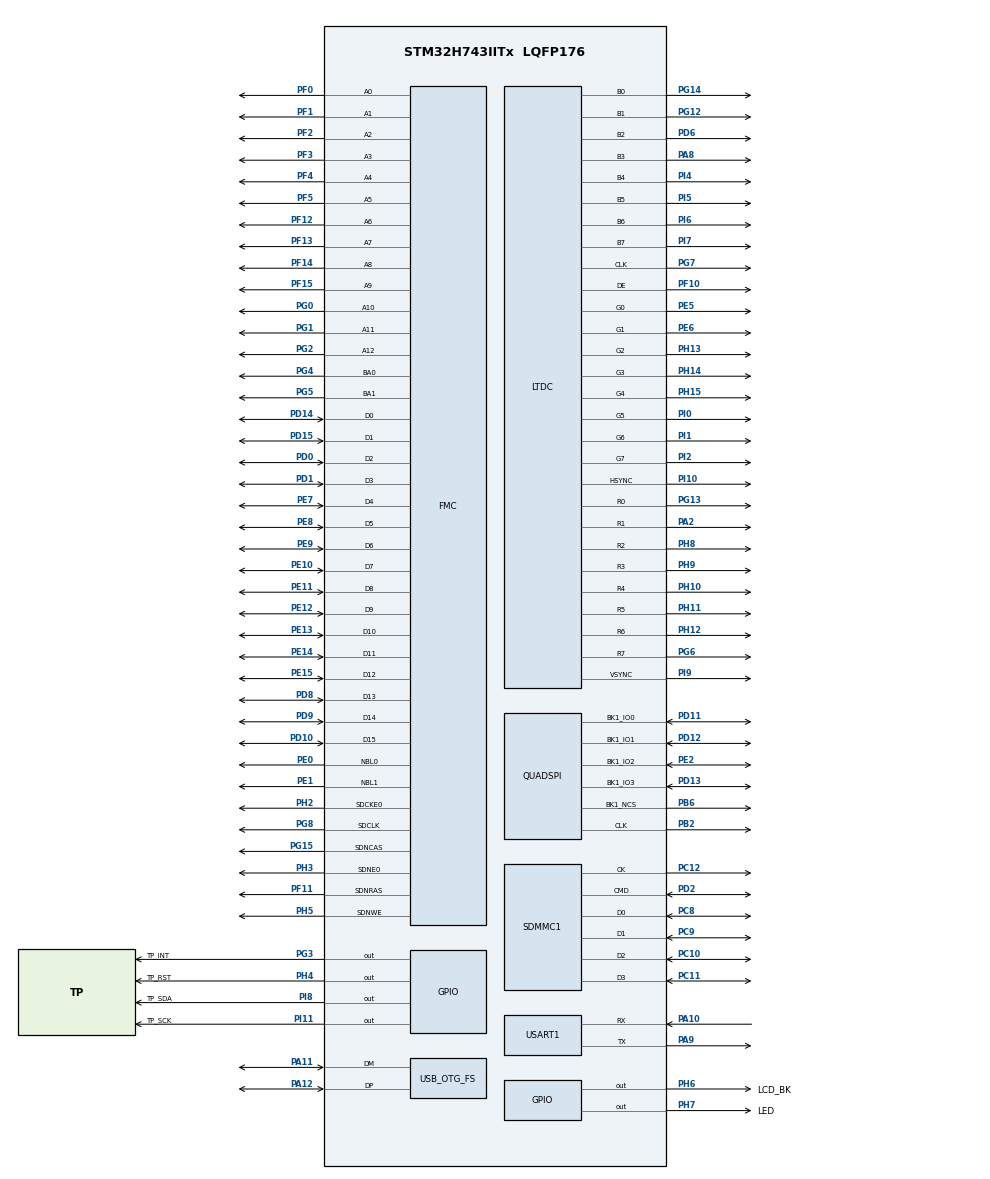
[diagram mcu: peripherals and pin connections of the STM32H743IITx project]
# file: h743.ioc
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CORTEX_M7.AccessPermission-Cortex_Memory_Protection_Unit_Region0_Settings=MPU_REGION_FULL_ACCESS
CORTEX_M7.AccessPermission-Cortex_Memory_Protection_Unit_Region1_Settings=MPU_REGION_FULL_ACCESS
CORTEX_M7.BaseAddress-Cortex_Memory_Protection_Unit_Region0_Settings=0xC0000000
CORTEX_M7.BaseAddress-Cortex_Memory_Protection_Unit_Region1_Settings=0x30000000
CORTEX_M7.CPU_DCache=Enabled
CORTEX_M7.CPU_ICache=Enabled
CORTEX_M7.DisableExec-Cortex_Memory_Protection_Unit_Region1_Settings=MPU_INSTRUCTION_ACCESS_DISABLE
CORTEX_M7.Enable-Cortex_Memory_Protection_Unit_Region0_Settings=MPU_REGION_ENABLE
CORTEX_M7.Enable-Cortex_Memory_Protection_Unit_Region1_Settings=MPU_REGION_ENABLE
CORTEX_M7.IsCacheable-Cortex_Memory_Protection_Unit_Region0_Settings=MPU_ACCESS_CACHEABLE
CORTEX_M7.IsShareable-Cortex_Memory_Protection_Unit_Region1_Settings=MPU_ACCESS_SHAREABLE
CORTEX_M7.MPU_Control=MPU_PRIVILEGED_DEFAULT
CORTEX_M7.Size-Cortex_Memory_Protection_Unit_Region0_Settings=MPU_REGION_SIZE_32MB
CORTEX_M7.Size-Cortex_Memory_Protection_Unit_Region1_Settings=MPU_REGION_SIZE_256KB
Dma.Request0=USART1_RX
Dma.Request1=USART1_TX
Dma.USART1_RX.0.Direction=DMA_PERIPH_TO_MEMORY
Dma.USART1_RX.0.EventEnable=DISABLE
Dma.USART1_RX.0.FIFOMode=DMA_FIFOMODE_DISABLE
Dma.USART1_RX.0.Instance=DMA1_Stream0
Dma.USART1_RX.0.MemDataAlignment=DMA_MDATAALIGN_BYTE
Dma.USART1_RX.0.MemInc=DMA_MINC_ENABLE
Dma.USART1_RX.0.Mode=DMA_NORMAL
Dma.USART1_RX.0.PeriphDataAlignment=DMA_PDATAALIGN_BYTE
Dma.USART1_RX.0.PeriphInc=DMA_PINC_DISABLE
Dma.USART1_RX.0.Polarity=HAL_DMAMUX_REQ_GEN_RISING
Dma.USART1_RX.0.Priority=DMA_PRIORITY_LOW
Dma.USART1_RX.0.RequestNumber=1
Dma.USART1_RX.0.SignalID=NONE
Dma.USART1_RX.0.SyncEnable=DISABLE
Dma.USART1_RX.0.SyncPolarity=HAL_DMAMUX_SYNC_NO_EVENT
Dma.USART1_RX.0.SyncRequestNumber=1
Dma.USART1_RX.0.SyncSignalID=NONE
Dma.USART1_TX.1.Direction=DMA_MEMORY_TO_PERIPH
Dma.USART1_TX.1.EventEnable=DISABLE
Dma.USART1_TX.1.FIFOMode=DMA_FIFOMODE_DISABLE
Dma.USART1_TX.1.Instance=DMA1_Stream1
Dma.USART1_TX.1.MemDataAlignment=DMA_MDATAALIGN_BYTE
Dma.USART1_TX.1.MemInc=DMA_MINC_ENABLE
Dma.USART1_TX.1.Mode=DMA_NORMAL
Dma.USART1_TX.1.PeriphDataAlignment=DMA_PDATAALIGN_BYTE
Dma.USART1_TX.1.PeriphInc=DMA_PINC_DISABLE
Dma.USART1_TX.1.Polarity=HAL_DMAMUX_REQ_GEN_RISING
Dma.USART1_TX.1.Priority=DMA_PRIORITY_LOW
Dma.USART1_TX.1.RequestNumber=1
Dma.USART1_TX.1.SignalID=NONE
Dma.USART1_TX.1.SyncEnable=DISABLE
Dma.USART1_TX.1.SyncPolarity=HAL_DMAMUX_SYNC_NO_EVENT
Dma.USART1_TX.1.SyncRequestNumber=1
Dma.USART1_TX.1.SyncSignalID=NONE
FMC.CASLatency1=FMC_SDRAM_CAS_LATENCY_3
FMC.ColumnBitsNumber1=FMC_SDRAM_COLUMN_BITS_NUM_9
FMC.ExitSelfRefreshDelay1=7
FMC.LoadToActiveDelay1=2
FMC.RPDelay1=2
FMC.RPDelay2=2
FMC.ReadBurst1=FMC_SDRAM_RBURST_ENABLE
FMC.ReadBurst2=FMC_SDRAM_RBURST_ENABLE
FMC.ReadPipeDelay1=FMC_SDRAM_RPIPE_DELAY_1
FMC.ReadPipeDelay2=FMC_SDRAM_RPIPE_DELAY_1
FMC.RowCycleDelay1=7
FMC.RowCycleDelay2=7
FMC.SDClockPeriod1=FMC_SDRAM_CLOCK_PERIOD_2
FMC.SDClockPeriod2=FMC_SDRAM_CLOCK_PERIOD_2
FMC.SelfRefreshTime1=4
FMC.WriteRecoveryTime1=2
LTDC.ActiveW=800
LTDC.Alpha_L0=255
LTDC.FBStartAdress_L0=0
LTDC.HBP=46
LTDC.HFP=200
LTDC.HSync=1
LTDC.ImageHeight_L0=480
LTDC.ImageWidth_L0=800
LTDC.Layers=0
LTDC.PixelFormat_L0=LTDC_PIXEL_FORMAT_RGB565
LTDC.VBP=23
LTDC.VFP=22
LTDC.VSync=1
LTDC.WindowX1_L0=800
LTDC.WindowY1_L0=480
Mcu.Family=STM32H7
Mcu.Name=STM32H743IITx
Mcu.Package=LQFP176
Mdma.MDMA_Channel0.QUADSPI_FIFO_TH.0.BlockCount=0
Mdma.MDMA_Channel0.QUADSPI_FIFO_TH.0.BlockDataLength=0
Mdma.MDMA_Channel0.QUADSPI_FIFO_TH.0.BufferTransferLength=128
Mdma.MDMA_Channel0.QUADSPI_FIFO_TH.0.CircularMode=MDMA_LINEAR_LIST
Mdma.MDMA_Channel0.QUADSPI_FIFO_TH.0.DataAlignment=MDMA_DATAALIGN_PACKENABLE
Mdma.MDMA_Channel0.QUADSPI_FIFO_TH.0.DestBlockAddressOffset=0
Mdma.MDMA_Channel0.QUADSPI_FIFO_TH.0.DestBurst=MDMA_DEST_BURST_SINGLE
Mdma.MDMA_Channel0.QUADSPI_FIFO_TH.0.DestDataSize=MDMA_DEST_DATASIZE_BYTE
Mdma.MDMA_Channel0.QUADSPI_FIFO_TH.0.DestinationInc=MDMA_DEST_INC_BYTE
Mdma.MDMA_Channel0.QUADSPI_FIFO_TH.0.DstAddress=0
Mdma.MDMA_Channel0.QUADSPI_FIFO_TH.0.Endianness=MDMA_LITTLE_ENDIANNESS_PRESERVE
Mdma.MDMA_Channel0.QUADSPI_FIFO_TH.0.Instance=MDMA_Channel0
Mdma.MDMA_Channel0.QUADSPI_FIFO_TH.0.MaskAddress=0
Mdma.MDMA_Channel0.QUADSPI_FIFO_TH.0.MaskData=0
Mdma.MDMA_Channel0.QUADSPI_FIFO_TH.0.Priority=MDMA_PRIORITY_VERY_HIGH
Mdma.MDMA_Channel0.QUADSPI_FIFO_TH.0.Rank=First
Mdma.MDMA_Channel0.QUADSPI_FIFO_TH.0.SourceBlockAddressOffset=0
Mdma.MDMA_Channel0.QUADSPI_FIFO_TH.0.SourceBurst=MDMA_SOURCE_BURST_SINGLE
Mdma.MDMA_Channel0.QUADSPI_FIFO_TH.0.SourceDataSize=MDMA_SRC_DATASIZE_BYTE
Mdma.MDMA_Channel0.QUADSPI_FIFO_TH.0.SourceInc=MDMA_SRC_INC_BYTE
Mdma.MDMA_Channel0.QUADSPI_FIFO_TH.0.SrcAddress=0
Mdma.MDMA_Channel0.QUADSPI_FIFO_TH.0.TransferTriggerMode=MDMA_BUFFER_TRANSFER
Mdma.MDMA_Channel0.Request0=QUADSPI_FIFO_TH
Mdma.MDMA_Channel0.RequestsNb=1
Mdma.RequestSet0=MDMA_Channel0
Mdma.RequestSetsNb=1
NVIC.DMA1_Stream0_IRQn=true\:5\:0\:true\:false\:true\:false\:true\:true
NVIC.DMA1_Stream1_IRQn=true\:5\:0\:true\:false\:true\:false\:true\:true
NVIC.LTDC_IRQn=true\:5\:0\:true\:false\:true\:true\:true\:true
NVIC.MDMA_IRQn=true\:5\:0\:true\:false\:true\:false\:true\:true
NVIC.PriorityGroup=NVIC_PRIORITYGROUP_4
NVIC.QUADSPI_IRQn=true\:5\:0\:true\:false\:true\:true\:true\:true
NVIC.SDMMC1_IRQn=true\:5\:0\:true\:false\:true\:true\:true\:true
NVIC.TIM7_IRQn=true\:15\:0\:false\:false\:true\:false\:true\:true
NVIC.TimeBase=TIM7_IRQn
NVIC.TimeBaseIP=TIM7
NVIC.USART1_IRQn=true\:5\:0\:true\:false\:true\:true\:true\:true
PA10.Mode=Asynchronous
PA10.Signal=USART1_RX
PA11.Mode=Device_Only
PA11.Signal=USB_OTG_FS_DM
PA12.Mode=Device_Only
PA12.Signal=USB_OTG_FS_DP
PA13\ (JTMS/SWDIO).Mode=Serial_Wire
PA13\ (JTMS/SWDIO).Signal=DEBUG_JTMS-SWDIO
PA14\ (JTCK/SWCLK).Mode=Serial_Wire
PA14\ (JTCK/SWCLK).Signal=DEBUG_JTCK-SWCLK
PA2.GPIO_Speed=GPIO_SPEED_FREQ_VERY_HIGH
PA2.Mode=RGB888
PA2.Signal=LTDC_R1
PA8.GPIO_Speed=GPIO_SPEED_FREQ_VERY_HIGH
PA8.Mode=RGB888
PA8.Signal=LTDC_B3
PA9.Mode=Asynchronous
PA9.Signal=USART1_TX
PB2.GPIO_Speed=GPIO_SPEED_FREQ_VERY_HIGH
PB2.Mode=Single Bank 1
PB2.Signal=QUADSPI_CLK
PB6.GPIO_Speed=GPIO_SPEED_FREQ_VERY_HIGH
PB6.Mode=Single Bank 1
PB6.Signal=QUADSPI_BK1_NCS
PC10.Mode=SD_4_bits_Wide_bus
PC10.Signal=SDMMC1_D2
PC11.Mode=SD_4_bits_Wide_bus
PC11.Signal=SDMMC1_D3
PC12.Mode=SD_4_bits_Wide_bus
PC12.Signal=SDMMC1_CK
PC14-OSC32_IN\ (OSC32_IN).Mode=LSE-External-Oscillator
PC14-OSC32_IN\ (OSC32_IN).Signal=RCC_OSC32_IN
PC15-OSC32_OUT\ (OSC32_OUT).Mode=LSE-External-Oscillator
PC15-OSC32_OUT\ (OSC32_OUT).Signal=RCC_OSC32_OUT
PC8.Mode=SD_4_bits_Wide_bus
PC8.Signal=SDMMC1_D0
PC9.Mode=SD_4_bits_Wide_bus
PC9.Signal=SDMMC1_D1
PD0.Signal=FMC_D2_DA2
PD1.Signal=FMC_D3_DA3
PD10.Signal=FMC_D15_DA15
PD11.GPIO_Speed=GPIO_SPEED_FREQ_VERY_HIGH
PD11.Mode=Single Bank 1
PD11.Signal=QUADSPI_BK1_IO0
PD12.GPIO_Speed=GPIO_SPEED_FREQ_VERY_HIGH
PD12.Mode=Single Bank 1
PD12.Signal=QUADSPI_BK1_IO1
PD13.GPIO_Speed=GPIO_SPEED_FREQ_VERY_HIGH
PD13.Mode=Single Bank 1
PD13.Signal=QUADSPI_BK1_IO3
PD14.Signal=FMC_D0_DA0
PD15.Signal=FMC_D1_DA1
PD2.Mode=SD_4_bits_Wide_bus
PD2.Signal=SDMMC1_CMD
PD6.GPIO_Speed=GPIO_SPEED_FREQ_VERY_HIGH
PD6.Mode=RGB888
PD6.Signal=LTDC_B2
PD8.Signal=FMC_D13_DA13
PD9.Signal=FMC_D14_DA14
PE0.Signal=FMC_NBL0
PE1.Signal=FMC_NBL1
PE10.Signal=FMC_D7_DA7
PE11.Signal=FMC_D8_DA8
PE12.Signal=FMC_D9_DA9
PE13.Signal=FMC_D10_DA10
PE14.Signal=FMC_D11_DA11
PE15.Signal=FMC_D12_DA12
PE2.GPIO_Speed=GPIO_SPEED_FREQ_VERY_HIGH
PE2.Mode=Single Bank 1
PE2.Signal=QUADSPI_BK1_IO2
PE5.GPIO_Speed=GPIO_SPEED_FREQ_VERY_HIGH
PE5.Mode=RGB888
PE5.Signal=LTDC_G0
PE6.GPIO_Speed=GPIO_SPEED_FREQ_VERY_HIGH
PE6.Mode=RGB888
PE6.Signal=LTDC_G1
PE7.Signal=FMC_D4_DA4
PE8.Signal=FMC_D5_DA5
PE9.Signal=FMC_D6_DA6
PF0.Signal=FMC_A0
PF1.Signal=FMC_A1
PF10.GPIO_Speed=GPIO_SPEED_FREQ_VERY_HIGH
PF10.Mode=RGB888
PF10.Signal=LTDC_DE
PF11.Signal=FMC_SDNRAS
PF12.Signal=FMC_A6
PF13.Signal=FMC_A7
PF14.Signal=FMC_A8
PF15.Signal=FMC_A9
PF2.Signal=FMC_A2
PF3.Signal=FMC_A3
PF4.Signal=FMC_A4
PF5.Signal=FMC_A5
PG0.Signal=FMC_A10
PG1.Signal=FMC_A11
PG12.GPIO_Speed=GPIO_SPEED_FREQ_VERY_HIGH
PG12.Mode=RGB888
PG12.Signal=LTDC_B1
PG13.GPIO_Speed=GPIO_SPEED_FREQ_VERY_HIGH
PG13.Mode=RGB888
PG13.Signal=LTDC_R0
PG14.GPIO_Speed=GPIO_SPEED_FREQ_VERY_HIGH
PG14.Mode=RGB888
PG14.Signal=LTDC_B0
PG15.Signal=FMC_SDNCAS
PG2.Signal=FMC_A12
PG3.GPIO_Label=TP_INT
PG3.Signal=GPIO_Output
PG4.Signal=FMC_A14_BA0
PG5.Signal=FMC_A15_BA1
PG6.GPIO_Speed=GPIO_SPEED_FREQ_VERY_HIGH
PG6.Mode=RGB888
PG6.Signal=LTDC_R7
PG7.GPIO_Speed=GPIO_SPEED_FREQ_VERY_HIGH
PG7.Mode=RGB888
PG7.Signal=LTDC_CLK
PG8.Signal=FMC_SDCLK
PH0-OSC_IN\ (PH0).Mode=HSE-External-Oscillator
PH0-OSC_IN\ (PH0).Signal=RCC_OSC_IN
PH1-OSC_OUT\ (PH1).Mode=HSE-External-Oscillator
PH1-OSC_OUT\ (PH1).Signal=RCC_OSC_OUT
PH10.GPIO_Speed=GPIO_SPEED_FREQ_VERY_HIGH
PH10.Mode=RGB888
PH10.Signal=LTDC_R4
PH11.GPIO_Speed=GPIO_SPEED_FREQ_VERY_HIGH
PH11.Mode=RGB888
PH11.Signal=LTDC_R5
PH12.GPIO_Speed=GPIO_SPEED_FREQ_VERY_HIGH
PH12.Mode=RGB888
PH12.Signal=LTDC_R6
PH13.GPIO_Speed=GPIO_SPEED_FREQ_VERY_HIGH
PH13.Mode=RGB888
PH13.Signal=LTDC_G2
PH14.GPIO_Speed=GPIO_SPEED_FREQ_VERY_HIGH
PH14.Mode=RGB888
PH14.Signal=LTDC_G3
PH15.GPIO_Speed=GPIO_SPEED_FREQ_VERY_HIGH
PH15.Mode=RGB888
PH15.Signal=LTDC_G4
PH2.Mode=SdramChipSelect1_1
PH2.Signal=FMC_SDCKE0
PH3.Mode=SdramChipSelect1_1
PH3.Signal=FMC_SDNE0
PH4.GPIO_Label=TP_RST
PH4.Signal=GPIO_Output
PH5.Signal=FMC_SDNWE
PH6.GPIO_Label=LCD_BK
PH6.Signal=GPIO_Output
PH7.GPIO_Label=LED
PH7.Signal=GPIO_Output
PH8.GPIO_Speed=GPIO_SPEED_FREQ_VERY_HIGH
PH8.Mode=RGB888
PH8.Signal=LTDC_R2
PH9.GPIO_Speed=GPIO_SPEED_FREQ_VERY_HIGH
PH9.Mode=RGB888
PH9.Signal=LTDC_R3
PI0.GPIO_Speed=GPIO_SPEED_FREQ_VERY_HIGH
PI0.Mode=RGB888
PI0.Signal=LTDC_G5
PI1.GPIO_Speed=GPIO_SPEED_FREQ_VERY_HIGH
PI1.Mode=RGB888
PI1.Signal=LTDC_G6
PI10.GPIO_Speed=GPIO_SPEED_FREQ_VERY_HIGH
PI10.Mode=RGB888
PI10.Signal=LTDC_HSYNC
PI11.GPIO_Label=TP_SCK
PI11.Signal=GPIO_Output
PI2.GPIO_Speed=GPIO_SPEED_FREQ_VERY_HIGH
PI2.Mode=RGB888
PI2.Signal=LTDC_G7
PI4.GPIO_Speed=GPIO_SPEED_FREQ_VERY_HIGH
PI4.Mode=RGB888
PI4.Signal=LTDC_B4
PI5.GPIO_Speed=GPIO_SPEED_FREQ_VERY_HIGH
PI5.Mode=RGB888
PI5.Signal=LTDC_B5
PI6.GPIO_Speed=GPIO_SPEED_FREQ_VERY_HIGH
PI6.Mode=RGB888
PI6.Signal=LTDC_B6
PI7.GPIO_Speed=GPIO_SPEED_FREQ_VERY_HIGH
PI7.Mode=RGB888
PI7.Signal=LTDC_B7
PI8.GPIO_Label=TP_SDA
PI8.Signal=GPIO_Output
PI9.GPIO_Speed=GPIO_SPEED_FREQ_VERY_HIGH
PI9.Mode=RGB888
PI9.Signal=LTDC_VSYNC
ProjectManager.HeapSize=0x200
ProjectManager.StackSize=0x400
ProjectManager.TargetToolchain=STM32CubeIDE
QUADSPI.ChipSelectHighTime=QSPI_CS_HIGH_TIME_1_CYCLE
QUADSPI.ClockMode=QSPI_CLOCK_MODE_3
QUADSPI.ClockPrescaler=3-1
QUADSPI.FifoThreshold=32
QUADSPI.FlashSize=22
QUADSPI.SampleShifting=QSPI_SAMPLE_SHIFTING_HALFCYCLE
RCC.ADCFreq_Value=100000000
RCC.APB1Freq_Value=120000000
RCC.APB2Freq_Value=120000000
RCC.APB3Freq_Value=120000000
RCC.APB4Freq_Value=120000000
RCC.CortexFreq_Value=480000000
RCC.D1PPRE=RCC_APB3_DIV2
RCC.D2PPRE1=RCC_APB1_DIV2
RCC.D2PPRE2=RCC_APB2_DIV2
RCC.D3PPRE=RCC_APB4_DIV2
RCC.DIVM1=5
RCC.DIVM2=2
RCC.DIVM3=25
RCC.DIVN1=192
RCC.DIVN2=16
RCC.DIVN3=330
RCC.DIVQ1=20
RCC.DIVR1=4
RCC.DIVR2=1
RCC.DIVR3=10
RCC.FMCCLockSelection=RCC_FMCCLKSOURCE_PLL2
RCC.HCLKFreq_Value=240000000
RCC.HPRE=RCC_HCLK_DIV2
RCC.PLL2FRACN=0
RCC.PLL3FRACN=0
RCC.PLLFRACN=0
RCC.PLLSourceVirtual=RCC_PLLSOURCE_HSE
RCC.RTCClockSelection=RCC_RTCCLKSOURCE_LSE
RCC.SYSCLKFreq_VALUE=480000000
RCC.SYSCLKSource=RCC_SYSCLKSOURCE_PLLCLK
RCC.USBCLockSelection=RCC_USBCLKSOURCE_HSI48
RCC.USBFreq_Value=48000000
SDMMC1.ClockDiv=2
SH.FMC_A0.0=FMC_A0,13b-sda1
SH.FMC_A1.0=FMC_A1,13b-sda1
SH.FMC_A10.0=FMC_A10,13b-sda1
SH.FMC_A11.0=FMC_A11,13b-sda1
SH.FMC_A12.0=FMC_A12,13b-sda1
SH.FMC_A14_BA0.0=FMC_BA0,FourSdramBanks1
SH.FMC_A15_BA1.0=FMC_BA1,FourSdramBanks1
SH.FMC_A2.0=FMC_A2,13b-sda1
SH.FMC_A3.0=FMC_A3,13b-sda1
SH.FMC_A4.0=FMC_A4,13b-sda1
SH.FMC_A5.0=FMC_A5,13b-sda1
SH.FMC_A6.0=FMC_A6,13b-sda1
SH.FMC_A7.0=FMC_A7,13b-sda1
SH.FMC_A8.0=FMC_A8,13b-sda1
SH.FMC_A9.0=FMC_A9,13b-sda1
SH.FMC_D0_DA0.0=FMC_D0,sd-16b-d1
SH.FMC_D10_DA10.0=FMC_D10,sd-16b-d1
SH.FMC_D11_DA11.0=FMC_D11,sd-16b-d1
SH.FMC_D12_DA12.0=FMC_D12,sd-16b-d1
SH.FMC_D13_DA13.0=FMC_D13,sd-16b-d1
SH.FMC_D14_DA14.0=FMC_D14,sd-16b-d1
SH.FMC_D15_DA15.0=FMC_D15,sd-16b-d1
SH.FMC_D1_DA1.0=FMC_D1,sd-16b-d1
SH.FMC_D2_DA2.0=FMC_D2,sd-16b-d1
SH.FMC_D3_DA3.0=FMC_D3,sd-16b-d1
SH.FMC_D4_DA4.0=FMC_D4,sd-16b-d1
SH.FMC_D5_DA5.0=FMC_D5,sd-16b-d1
SH.FMC_D6_DA6.0=FMC_D6,sd-16b-d1
SH.FMC_D7_DA7.0=FMC_D7,sd-16b-d1
SH.FMC_D8_DA8.0=FMC_D8,sd-16b-d1
SH.FMC_D9_DA9.0=FMC_D9,sd-16b-d1
SH.FMC_NBL0.0=FMC_NBL0,Sd2ByteEnable1
SH.FMC_NBL1.0=FMC_NBL1,Sd2ByteEnable1
SH.FMC_SDCLK.0=FMC_SDCLK,13b-sda1
SH.FMC_SDNCAS.0=FMC_SDNCAS,13b-sda1
SH.FMC_SDNRAS.0=FMC_SDNRAS,13b-sda1
SH.FMC_SDNWE.0=FMC_SDNWE,13b-sda1
USART1.VirtualMode-Asynchronous=VM_ASYNC
USB_OTG_FS.VirtualMode=Device_Only
VP_DMA2D_VS_DMA2D.Mode=DMA2D_Activate
VP_MEMORYMAP_VS_MEMORYMAP.Mode=CurAppReg
VP_RTC_VS_RTC_Activate.Mode=RTC_Enabled
VP_RTC_VS_RTC_Calendar.Mode=RTC_Calendar
VP_SYS_VS_tim7.Mode=TIM7
board=custom

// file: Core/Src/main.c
/* USER CODE BEGIN Header */
/**
  ******************************************************************************
  * @file           : main.c
  * @brief          : Main program body
  ******************************************************************************
  * @attention
  *
  * Copyright (c) 2026 STMicroelectronics.
  * All rights reserved.
  *
  * This software is licensed under terms that can be found in the LICENSE file
  * in the root directory of this software component.
  * If no LICENSE file comes with this software, it is provided AS-IS.
  *
  ******************************************************************************
  */
/* USER CODE END Header */
#include "main.h"
#include "dma.h"
#include "dma2d.h"
#include "ltdc.h"
#include "mdma.h"
#include "quadspi.h"
#include "rtc.h"
#include "sdmmc.h"
#include "usart.h"
#include "usb_otg.h"
#include "gpio.h"
#include "fmc.h"

/* USER CODE BEGIN Includes */
#include <string.h>
#include <stdio.h>
#include <stdarg.h>
#include <fcntl.h>
#include <unistd.h>
#include <time.h>

#include "fatfs_port.h"
#include "bsp/board_api.h"
#include "qspi_w25q64.h"
#include "tusb_port.h"
#include "sdram.h"
#include "mem.h"
#include "freertos_port.h"
#include "sd.h"
#include "tlsf_port.h"
#include "lcd.h"
#include "uart.h"
#include "usb_msc.h"
#include "usb_vdb.h"
#include "lcd.h"
#include "lv_port.h"
#include "lvgl.h"
#include "touch.h"
/* USER CODE END Includes */

void SystemClock_Config(void);
static void MPU_Config(void);

/* USER CODE BEGIN 0 */

// Zeller 公式计算星期几 (RTC编码: 1=Mon..7=Sun)
static int calc_weekday(int year, int month, int day)
{
    // Zeller's congruence (Gregorian calendar)
    if (month < 3) { month += 12; year--; }
    int k = year % 100;
    int j = year / 100;
    int h = (day + (13 * (month + 1)) / 5 + k + k / 4 + j / 4 - 2 * j) % 7;
    if (h < 0) h += 7;
    // h: 0=Sat, 1=Sun, 2=Mon ... 6=Fri
    // RTC: 1=Mon, 2=Tue, 3=Wed, 4=Thu, 5=Fri, 6=Sat, 7=Sun
    static const int map[] = {6, 7, 1, 2, 3, 4, 5};
    return map[h];
}

// 解析 __DATE__/__TIME__ 编译时间写入RTC (编译时刻=启动时间)
static void set_rtc_from_build_time(void)
{
    static const char *months[] = {
        "Jan", "Feb", "Mar", "Apr", "May", "Jun",
        "Jul", "Aug", "Sep", "Oct", "Nov", "Dec"
    };

    RTC_TimeTypeDef sTime = {0};
    RTC_DateTypeDef sDate = {0};

    int hour, minute, second;
    sscanf(__TIME__, "%d:%d:%d", &hour, &minute, &second);
    sTime.Hours   = hour;
    sTime.Minutes = minute;
    sTime.Seconds = second;
    sTime.DayLightSaving = RTC_DAYLIGHTSAVING_NONE;
    sTime.StoreOperation = RTC_STOREOPERATION_RESET;

    char mon_str[4];
    int day, year;
    sscanf(__DATE__, "%3s %d %d", mon_str, &day, &year);

    int month = 1;
    for (int i = 0; i < 12; i++) {
        if (strncmp(mon_str, months[i], 3) == 0) {
            month = i + 1;
            break;
        }
    }

    sDate.WeekDay = calc_weekday(year, month, day);
    sDate.Month   = month;
    sDate.Date    = day;
    sDate.Year    = year - 2000;

    HAL_RTC_SetTime(&hrtc, &sTime, RTC_FORMAT_BIN);
    HAL_RTC_SetDate(&hrtc, &sDate, RTC_FORMAT_BIN);
}

#if BSP_FREERTOS_ENABLED
static StackType_t  led_task_stack[128];
static StaticTask_t led_task_tcb;
// LED 闪烁任务 (100ms 周期, FreeRTOS)
static void led_task(void *pvParameters)
{
    (void)pvParameters;
    for (;;) {
        HAL_GPIO_TogglePin(LED_GPIO_Port, LED_Pin);
        vTaskDelay(pdMS_TO_TICKS(100));
    }
}

static StackType_t  usb_task_stack[512];
static StaticTask_t usb_task_tcb;
// USB 设备轮询任务 (1ms 周期, FreeRTOS)
static void usb_task(void *pvParameters)
{
    (void)pvParameters;
    for (;;) {
        tusb_port_task();
        usb_vdb_poll();
        vTaskDelay(pdMS_TO_TICKS(1));
    }
}

static StackType_t  lvgl_task_stack[4096];
static StaticTask_t lvgl_task_tcb;
// LVGL 任务: 初始化显示 + timer 心跳 (FreeRTOS)
static void lvgl_task(void *pvParameters)
{
  (void)pvParameters;
  lv_port_init();

  // 简单按钮示例
  lv_obj_t *btn = lv_slider_create(lv_screen_active());
  lv_obj_set_size(btn, 600, 50);
  lv_obj_center(btn);

  for (;;) {
    lv_timer_handler();
    vTaskDelay(pdMS_TO_TICKS(5));
  };
}

static StackType_t  touch_task_stack[256];
static StaticTask_t touch_task_tcb;
// 触摸扫描任务 (10ms 周期, FreeRTOS)
static void touch_task(void *pvParameters)
{
    (void)pvParameters;
    for (;;) {
        touch_scan();
        if (touch_is_touch()) {
            uint16_t x, y;
            touch_read_xy(0, &x, &y);
        }
        vTaskDelay(pdMS_TO_TICKS(10));
    }
}

static StackType_t  init_task_stack[1024];
static StaticTask_t init_task_tcb;
static char buff[64];
// 初始化任务: RTOS资源/LCD测试/UART回传+时间戳 (FreeRTOS)
static void init_task(void *pvParameters)
{
    (void)pvParameters;
    tlsf_port_rtos_init();
    sd_rtos_init();
    uart_rtos_init();
    touch_rtos_init();

    xTaskCreateStatic(led_task, "led", 128, NULL, 1,
                       led_task_stack, &led_task_tcb);
    xTaskCreateStatic(usb_task, "usb", 512, NULL, 2,
                       usb_task_stack, &usb_task_tcb);
    xTaskCreateStatic(lvgl_task, "lvgl", 4096, NULL, 4,
                       lvgl_task_stack, &lvgl_task_tcb);
    xTaskCreateStatic(touch_task, "touch", 256, NULL, 1,
                       touch_task_stack, &touch_task_tcb);

    int uart = open("/dev/uart/COM0", O_RDWR);
    if (uart == -1) {
      printf("open failed\n");
      return;
    }

    while (1) {
      int s = read(uart, buff, sizeof(buff));
      if (s > 0) {
        time_t now = time(NULL);
        struct tm *tm_info = localtime(&now);
        char time_str[64];
        int n = strftime(time_str, sizeof(time_str),
                         "[%Y-%m-%d %H:%M:%S] ", tm_info);
        if (n > 0) {
          write(uart, time_str, n);
        }
        write(uart, buff, s);
      }
      vTaskDelay(pdMS_TO_TICKS(10));
    };
}

#endif
/* USER CODE END 0 */

int main(void)
{

  /* MPU Configuration--------------------------------------------------------*/
  MPU_Config();

  /* Enable the CPU Cache */

  /* Enable I-Cache---------------------------------------------------------*/
  SCB_EnableICache();

  /* Enable D-Cache---------------------------------------------------------*/
  SCB_EnableDCache();

  /* MCU Configuration--------------------------------------------------------*/

  /* Reset of all peripherals, Initializes the Flash interface and the Systick. */
  HAL_Init();

  /* Configure the system clock */
  SystemClock_Config();

  /* Initialize all configured peripherals */
  MX_GPIO_Init();
  MX_MDMA_Init();
  MX_DMA_Init();
  MX_QUADSPI_Init();
  MX_USB_OTG_FS_PCD_Init();
  MX_USART1_UART_Init();
  MX_FMC_Init();
  MX_SDMMC1_SD_Init();
  MX_RTC_Init();
  MX_LTDC_Init();
  MX_DMA2D_Init();
  /* USER CODE BEGIN 2 */
  set_rtc_from_build_time();
  qspi_w25q64_init();              // 初始化W25Q64
  qspi_w25q64_memory_mapped_mode(); // 启用内存映射，之后才能读 EX_FLASH
  FMC_SDRAM_CommandTypeDef command;	// 控制指令
  sdram_init_sequence(&hsdram1,&command);
  mem_itcm_load();       // 搬运 ITCM 函数
  mem_sdram_load();      // 搬运 SDRAM 函数 (从 EX_FLASH 读取)
  tlsf_port_init();
  sd_init();              // 初始化 SD 卡
  fatfs_port_init();      // 挂载 SD 卡文件系统 (f_mount)
  fatfs_port_vfs_init();  // 注册 VFS 节点 (根 "/sd")
  usb_msc_init();         // 缓存 SD 卡信息 (必须在 tusb_port_init 之前)
  usb_vdb_init();          // 初始化 USB VDB
  tusb_port_init();       // 初始化 TinyUSB 设备
  uart_init();                     // UART RXNE 中断在硬件初始化完成后才开启
  uart_vfs_init();
  lcd_init();
  touch_init();

#if BSP_FREERTOS_ENABLED
  xTaskCreateStatic(init_task, "init", 1024, NULL, 3,
                     init_task_stack, &init_task_tcb);
  freertos_port_init();
#endif
  /* USER CODE END 2 */

  /* Infinite loop */
  /* USER CODE BEGIN WHILE */
#if !BSP_FREERTOS_ENABLED
  lv_port_init();
  lv_tick_set_cb(lv_port_tick_get);

  lv_obj_t *btn = lv_button_create(lv_screen_active());
  lv_obj_set_size(btn, 120, 50);
  lv_obj_center(btn);
  lv_obj_t *label = lv_label_create(btn);
  lv_label_set_text(label, "Hello");
  lv_obj_center(label);

  uint32_t t = HAL_GetTick();
  touch_init();
  while (1)
  {
    lv_timer_handler();
    touch_scan();
    if (touch_is_touch()) {
      uint16_t x, y;
      touch_read_xy(0, &x, &y);
      DEBUG_PRINT("Touch: %d pts, x0=%d y0=%d\r\n",
                  touch_get_num(), x, y);
    }
    if (HAL_GetTick()-t > 100) {
      HAL_GPIO_TogglePin(LED_GPIO_Port, LED_Pin);
      t = HAL_GetTick();
    }
    /* USER CODE END WHILE */

    /* USER CODE BEGIN 3 */
  }
#endif
  /* USER CODE END 3 */
}

void SystemClock_Config(void)
{
  RCC_OscInitTypeDef RCC_OscInitStruct = {0};
  RCC_ClkInitTypeDef RCC_ClkInitStruct = {0};

  /** Supply configuration update enable
  */
  HAL_PWREx_ConfigSupply(PWR_LDO_SUPPLY);

  /** Configure the main internal regulator output voltage
  */
  __HAL_PWR_VOLTAGESCALING_CONFIG(PWR_REGULATOR_VOLTAGE_SCALE0);

  while(!__HAL_PWR_GET_FLAG(PWR_FLAG_VOSRDY)) {}

  /** Configure LSE Drive Capability
  */
  HAL_PWR_EnableBkUpAccess();
  __HAL_RCC_LSEDRIVE_CONFIG(RCC_LSEDRIVE_LOW);

  /** Initializes the RCC Oscillators according to the specified parameters
  * in the RCC_OscInitTypeDef structure.
  */
  RCC_OscInitStruct.OscillatorType = RCC_OSCILLATORTYPE_HSI48|RCC_OSCILLATORTYPE_HSE
                              |RCC_OSCILLATORTYPE_LSE;
  RCC_OscInitStruct.HSEState = RCC_HSE_ON;
  RCC_OscInitStruct.LSEState = RCC_LSE_ON;
  RCC_OscInitStruct.HSI48State = RCC_HSI48_ON;
  RCC_OscInitStruct.PLL.PLLState = RCC_PLL_ON;
  RCC_OscInitStruct.PLL.PLLSource = RCC_PLLSOURCE_HSE;
  RCC_OscInitStruct.PLL.PLLM = 5;
  RCC_OscInitStruct.PLL.PLLN = 192;
  RCC_OscInitStruct.PLL.PLLP = 2;
  RCC_OscInitStruct.PLL.PLLQ = 20;
  RCC_OscInitStruct.PLL.PLLR = 4;
  RCC_OscInitStruct.PLL.PLLRGE = RCC_PLL1VCIRANGE_2;
  RCC_OscInitStruct.PLL.PLLVCOSEL = RCC_PLL1VCOWIDE;
  RCC_OscInitStruct.PLL.PLLFRACN = 0;
  if (HAL_RCC_OscConfig(&RCC_OscInitStruct) != HAL_OK)
  {
    Error_Handler();
  }

  /** Initializes the CPU, AHB and APB buses clocks
  */
  RCC_ClkInitStruct.ClockType = RCC_CLOCKTYPE_HCLK|RCC_CLOCKTYPE_SYSCLK
                              |RCC_CLOCKTYPE_PCLK1|RCC_CLOCKTYPE_PCLK2
                              |RCC_CLOCKTYPE_D3PCLK1|RCC_CLOCKTYPE_D1PCLK1;
  RCC_ClkInitStruct.SYSCLKSource = RCC_SYSCLKSOURCE_PLLCLK;
  RCC_ClkInitStruct.SYSCLKDivider = RCC_SYSCLK_DIV1;
  RCC_ClkInitStruct.AHBCLKDivider = RCC_HCLK_DIV2;
  RCC_ClkInitStruct.APB3CLKDivider = RCC_APB3_DIV2;
  RCC_ClkInitStruct.APB1CLKDivider = RCC_APB1_DIV2;
  RCC_ClkInitStruct.APB2CLKDivider = RCC_APB2_DIV2;
  RCC_ClkInitStruct.APB4CLKDivider = RCC_APB4_DIV2;

  if (HAL_RCC_ClockConfig(&RCC_ClkInitStruct, FLASH_LATENCY_4) != HAL_OK)
  {
    Error_Handler();
  }
}

/* USER CODE BEGIN 4 */

#if BSP_FREERTOS_ENABLED
static StackType_t  idle_task_stack[configMINIMAL_STACK_SIZE];
static StaticTask_t idle_task_tcb;

void vApplicationGetIdleTaskMemory(StaticTask_t **ppxIdleTaskTCBBuffer,
                                   StackType_t **ppxIdleTaskStackBuffer,
                                   uint32_t *pulIdleTaskStackSize)
{
    *ppxIdleTaskTCBBuffer   = &idle_task_tcb;
    *ppxIdleTaskStackBuffer = idle_task_stack;
    *pulIdleTaskStackSize   = configMINIMAL_STACK_SIZE;
}
#endif

/* USER CODE END 4 */

 /* MPU Configuration */

void MPU_Config(void)
{
  MPU_Region_InitTypeDef MPU_InitStruct = {0};

  /* Disables the MPU */
  HAL_MPU_Disable();

  /** Initializes and configures the Region and the memory to be protected
  */
  MPU_InitStruct.Enable = MPU_REGION_ENABLE;
  MPU_InitStruct.Number = MPU_REGION_NUMBER0;
  MPU_InitStruct.BaseAddress = 0xC0000000;
  MPU_InitStruct.Size = MPU_REGION_SIZE_32MB;
  MPU_InitStruct.SubRegionDisable = 0x0;
  MPU_InitStruct.TypeExtField = MPU_TEX_LEVEL0;
  MPU_InitStruct.AccessPermission = MPU_REGION_FULL_ACCESS;
  MPU_InitStruct.DisableExec = MPU_INSTRUCTION_ACCESS_ENABLE;
  MPU_InitStruct.IsShareable = MPU_ACCESS_NOT_SHAREABLE;
  MPU_InitStruct.IsCacheable = MPU_ACCESS_CACHEABLE;
  MPU_InitStruct.IsBufferable = MPU_ACCESS_NOT_BUFFERABLE;

  HAL_MPU_ConfigRegion(&MPU_InitStruct);

  /** Initializes and configures the Region and the memory to be protected
  */
  MPU_InitStruct.Number = MPU_REGION_NUMBER1;
  MPU_InitStruct.BaseAddress = 0x30000000;
  MPU_InitStruct.Size = MPU_REGION_SIZE_256KB;
  MPU_InitStruct.DisableExec = MPU_INSTRUCTION_ACCESS_DISABLE;
  MPU_InitStruct.IsShareable = MPU_ACCESS_SHAREABLE;
  MPU_InitStruct.IsCacheable = MPU_ACCESS_NOT_CACHEABLE;

  HAL_MPU_ConfigRegion(&MPU_InitStruct);
  /* Enables the MPU */
  HAL_MPU_Enable(MPU_PRIVILEGED_DEFAULT);

}

void HAL_TIM_PeriodElapsedCallback(TIM_HandleTypeDef *htim)
{
  if (htim->Instance == TIM7)
  {
    HAL_IncTick();
  }
}

void Error_Handler(void)
{
  __disable_irq();
  while (1)
  {
  }
}
